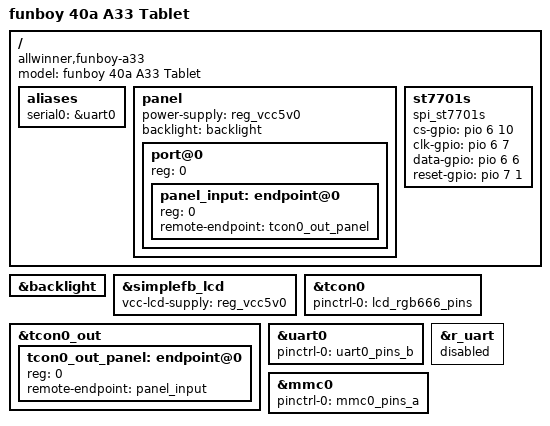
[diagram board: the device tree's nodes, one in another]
/*
 * Copyright 2015 Hans de Goede <hdegoede@redhat.com>
 *
 * This file is dual-licensed: you can use it either under the terms
 * of the GPL or the X11 license, at your option. Note that this dual
 * licensing only applies to this file, and not this project as a
 * whole.
 *
 *  a) This file is free software; you can redistribute it and/or
 *     modify it under the terms of the GNU General Public License as
 *     published by the Free Software Foundation; either version 2 of the
 *     License, or (at your option) any later version.
 *
 *     This file is distributed in the hope that it will be useful,
 *     but WITHOUT ANY WARRANTY; without even the implied warranty of
 *     MERCHANTABILITY or FITNESS FOR A PARTICULAR PURPOSE.  See the
 *     GNU General Public License for more details.
 *
 * Or, alternatively,
 *
 *  b) Permission is hereby granted, free of charge, to any person
 *     obtaining a copy of this software and associated documentation
 *     files (the "Software"), to deal in the Software without
 *     restriction, including without limitation the rights to use,
 *     copy, modify, merge, publish, distribute, sublicense, and/or
 *     sell copies of the Software, and to permit persons to whom the
 *     Software is furnished to do so, subject to the following
 *     conditions:
 *
 *     The above copyright notice and this permission notice shall be
 *     included in all copies or substantial portions of the Software.
 *
 *     THE SOFTWARE IS PROVIDED "AS IS", WITHOUT WARRANTY OF ANY KIND,
 *     EXPRESS OR IMPLIED, INCLUDING BUT NOT LIMITED TO THE WARRANTIES
 *     OF MERCHANTABILITY, FITNESS FOR A PARTICULAR PURPOSE AND
 *     NONINFRINGEMENT. IN NO EVENT SHALL THE AUTHORS OR COPYRIGHT
 *     HOLDERS BE LIABLE FOR ANY CLAIM, DAMAGES OR OTHER LIABILITY,
 *     WHETHER IN AN ACTION OF CONTRACT, TORT OR OTHERWISE, ARISING
 *     FROM, OUT OF OR IN CONNECTION WITH THE SOFTWARE OR THE USE OR
 *     OTHER DEALINGS IN THE SOFTWARE.
 */

/dts-v1/;
#include "sun8i-a33.dtsi"
#include "sun8i-q8-common.dtsi"

/ {
	model = "funboy 40a A33 Tablet";
	compatible = "allwinner,funboy-a33", "allwinner,sun8i-a33";
	aliases {
		serial0 = &uart0;
	};
	panel {
		#address-cells = <1>;
		#size-cells = <0>;
		power-supply = <&reg_vcc5v0>;
		backlight = <&backlight>;
		port@0 {
			reg = <0>;
			#address-cells = <1>;
			#size-cells = <0>;

			panel_input: endpoint@0 {
				reg = <0>;
				remote-endpoint = <&tcon0_out_panel>;
			};
		};
	};
	st7701s {
        compatible = "spi_st7701s";
        cs-gpio = <&pio 6 10 GPIO_ACTIVE_HIGH>; //PG 10
        clk-gpio = <&pio 6 7 GPIO_ACTIVE_HIGH>;  //PG7
        data-gpio = <&pio 6 6 GPIO_ACTIVE_HIGH>;  //PG6
        reset-gpio = <&pio 7 1 GPIO_ACTIVE_HIGH>; /* PH1 */
        status = "okay";
	};
};

&backlight{
	/delete-property/ enable-gpios;
	// enable-gpios = <&pio 7 1 GPIO_ACTIVE_HIGH>; /* PH1 */
};

&simplefb_lcd{
	status = "okay";
	vcc-lcd-supply = <&reg_vcc5v0>;
};

&tcon0 {
	pinctrl-names = "default";
	pinctrl-0 = <&lcd_rgb666_pins>;
	status = "okay";
};

&tcon0_out {
	tcon0_out_panel: endpoint@0 {
		reg = <0>;
		remote-endpoint = <&panel_input>;
	};
};

&uart0 {
	pinctrl-names = "default";
	pinctrl-0 = <&uart0_pins_b>;
	status = "okay";
};

&r_uart {
	status = "disabled";
};

&mmc0 {
	/delete-property/ cd-gpios;
        pinctrl-names = "default";
        pinctrl-0 = <&mmc0_pins_a>;
};

